# MIMXRT1064 register map
Vendor: nxp.com; File version: 1.0
CPU: CM7 r0p1, little endian, MPU, FPU, VTOR, 4 interrupt priority bits
Registers are 32-bit, read-write, reset 0x0 unless marked. A register's access mark holds for its fields unless they carry their own. Offsets are from the block's base; [hi:lo] are bit positions; {n}, {i} and the like mark numbered series; 'fields as' and 'values as' point back to an identical list.

## TMR1 — TMR
Base 0x401DC000
Same registers: TMR2 0x401E0000, TMR3 0x401E4000, TMR4 0x401E8000
0x00 COMP10 16-bit — Timer Channel Compare Register 1
  [15:0] COMPARISON_1 — Comparison Value 1
0x02 COMP20 16-bit — Timer Channel Compare Register 2
  [15:0] COMPARISON_2 — Comparison Value 2
{0x4+0x20*i} CAPT{i} 16-bit (i=0..3) — Timer Channel Capture Register
  [15:0] CAPTURE — Capture Value
{0x6+0x20*i} LOAD{i} 16-bit (i=0..3) — Timer Channel Load Register
  [15:0] LOAD — Timer Load Register
{0x8+0x20*i} HOLD{i} 16-bit (i=0..3) — Timer Channel Hold Register
  [15:0] HOLD
{0xA+0x20*i} CNTR{i} 16-bit (i=0..3) — Timer Channel Counter Register
  [15:0] COUNTER
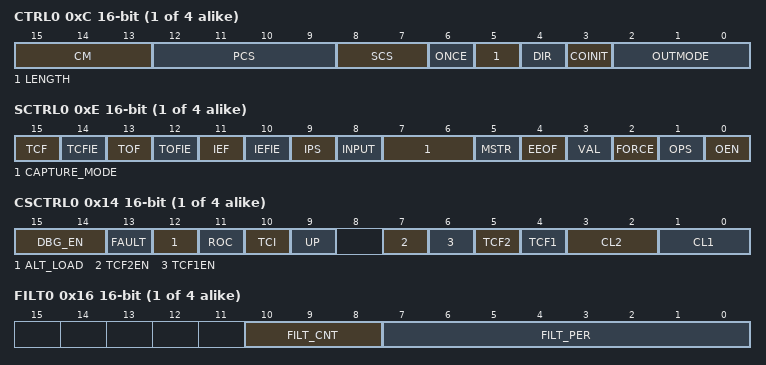
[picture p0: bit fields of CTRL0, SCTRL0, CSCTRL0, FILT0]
{0xC+0x20*i} CTRL{i} 16-bit (i=0..3) — Timer Channel Control Register
  [15:13] CM — Count Mode
    0=NOOP (No operation); 1=RISING_ONLY (Count rising edges of primary sourceRising edges are counted only when SCTRL[IPS] = 0. Falling edges are counted when SCTRL[IPS] = 1. If the primary count source is IP bus clock divide by 1, only rising edges are counted regardless of the value of SCTRL[IPS].); 2=RISING_AND_FALLING (Count rising and falling edges of primary sourceIP bus clock divide by 1 cannot be used as a primary count source in edge count mode.); 3=RISING_WHILE_SEC_HIGH (Count rising edges of primary source while secondary input high active); 4=QUADRATURE (Quadrature count mode, uses primary and secondary sources); 5=RISING_SEC_DIR (Count rising edges of primary source; secondary source specifies directionRising edges are counted only when SCTRL[IPS] = 0. Falling edges are counted when SCTRL[IPS] = 1.); 6=SECONDARY (Edge of secondary source triggers primary count until compare); 7=CASCADE (Cascaded counter mode (up/down)The primary count source must be set to one of the counter outputs.)
  [12:9] PCS — Primary Count Source
    {v}=COUNTER{v}_IN (Counter {v} input pin) (v=0..3); {v}=COUNTER{v-4}_OUT (Counter {v-4} output) (v=4..7); 8=BUS_DIVBY1 (IP bus clock divide by 1 prescaler); 9=BUS_DIVBY2 (IP bus clock divide by 2 prescaler); 10=BUS_DIVBY4 (IP bus clock divide by 4 prescaler); 11=BUS_DIVBY8 (IP bus clock divide by 8 prescaler); 12=BUS_DIVBY16 (IP bus clock divide by 16 prescaler); 13=BUS_DIVBY32 (IP bus clock divide by 32 prescaler); 14=BUS_DIVBY64 (IP bus clock divide by 64 prescaler); 15=BUS_DIVBY128 (IP bus clock divide by 128 prescaler)
  [8:7] SCS — Secondary Count Source
    {v}=COUNTER{v}_IN (Counter {v} input pin) (v=0..3)
  [6] ONCE — Count Once
    0=REPEAT (Count repeatedly.); 1=UNTIL_COMPARE (Count until compare and then stop. If counting up, a successful compare occurs when the counter reaches a COMP1 value. If counting down, a successful compare occurs when the counter reaches a COMP2 value. When output mode $4 is used, the counter re-initializes after reaching the COMP1 value, continues to count to the COMP2 value, and then stops.)
  [5] LENGTH — Count Length
    0=UNTIL_ROLLOVER (Count until roll over at $FFFF and continue from $0000.); 1=UNTIL_COMPARE (Count until compare, then re-initialize. If counting up, a successful compare occurs when the counter reaches a COMP1 value. If counting down, a successful compare occurs when the counter reaches a COMP2 value. When output mode $4 is used, alternating values of COMP1 and COMP2 are used to generate successful comparisons. For example, the counter counts until a COMP1 value is reached, re-initializes, counts until COMP2 value is reached, re-initializes, counts until COMP1 value is reached, and so on.)
  [4] DIR — Count Direction
    0=COUNTUP; 1=COUNTDOWN
  [3] COINIT — Co-Channel Initialization
    0=DISABLE (Co-channel counter/timers cannot force a re-initialization of this counter/timer); 1=ENABLE (Co-channel counter/timers may force a re-initialization of this counter/timer)
  [2:0] OUTMODE — Output Mode
    0=COUNTER_ACTIVE (Asserted while counter is active); 1=CLEAR_OFLAG (Clear OFLAG output on successful compare); 2=SET_OFLAG (Set OFLAG output on successful compare); 3=TOGGLE_OFLAG_SUCCESS (Toggle OFLAG output on successful compare); 4=TOGGLE_OFLAG_ALT (Toggle OFLAG output using alternating compare registers); 5=CLEAR_ON_SECONDARY (Set on compare, cleared on secondary source input edge); 6=CLEAR_ON_ROLLOVER (Set on compare, cleared on counter rollover); 7=ENABLE_GATED_OUT (Enable gated clock output while counter is active)
{0xE+0x20*i} SCTRL{i} 16-bit (i=0..3) — Timer Channel Status and Control Register
  [15] TCF — Timer Compare Flag
  [14] TCFIE — Timer Compare Flag Interrupt Enable
  [13] TOF — Timer Overflow Flag
  [12] TOFIE — Timer Overflow Flag Interrupt Enable
  [11] IEF — Input Edge Flag
  [10] IEFIE — Input Edge Flag Interrupt Enable
  [9] IPS — Input Polarity Select
  [8] INPUT ro — External Input Signal
  [7:6] CAPTURE_MODE — Input Capture Mode
    0=DISABLED (Capture function is disabled); 1=ENABLE_RISING (Load capture register on rising edge (when IPS=0) or falling edge (when IPS=1) of input); 2=ENABLE_FALLING (Load capture register on falling edge (when IPS=0) or rising edge (when IPS=1) of input); 3=ENABLE_BOTH (Load capture register on both edges of input)
  [5] MSTR — Master Mode
  [4] EEOF — Enable External OFLAG Force
  [3] VAL — Forced OFLAG Value
  [2] FORCE — Force OFLAG Output
  [1] OPS — Output Polarity Select
    0=TRUE (True polarity.); 1=INVERTED (Inverted polarity.)
  [0] OEN — Output Enable
    0=INPUT (The external pin is configured as an input.); 1=OFLAG_OUT (The OFLAG output signal is driven on the external pin. Other timer groups using this external pin as their input see the driven value. The polarity of the signal is determined by OPS.)
0x10 CMPLD10 16-bit — Timer Channel Comparator Load Register 1
  [15:0] COMPARATOR_LOAD_1
0x12 CMPLD20 16-bit — Timer Channel Comparator Load Register 2
  [15:0] COMPARATOR_LOAD_2
{0x14+0x20*i} CSCTRL{i} 16-bit (i=0..3) — Timer Channel Comparator Status and Control Register
  [15:14] DBG_EN — Debug Actions Enable
    0=NORMAL (Continue with normal operation during debug mode. (default)); 1=HALT_TMR (Halt TMR counter during debug mode.); 2=FORCE_0 (Force TMR output to logic 0 (prior to consideration of SCTRL[OPS]).); 3=HALT_AND_FORCE_0 (Both halt counter and force output to 0 during debug mode.)
  [13] FAULT — Fault Enable
    0=DISABLE (Fault function disabled.); 1=ENABLE (Fault function enabled.)
  [12] ALT_LOAD — Alternative Load Enable
    0=DISABLE (Counter can be re-initialized only with the LOAD register.); 1=ENABLE (Counter can be re-initialized with the LOAD or CMPLD2 registers depending on count direction.)
  [11] ROC — Reload on Capture
    0=DISABLE (Do not reload the counter on a capture event.); 1=ENABLE (Reload the counter on a capture event.)
  [10] TCI — Triggered Count Initialization Control
    0=STOP (Stop counter upon receiving a second trigger event while still counting from the first trigger event.); 1=RELOAD (Reload the counter upon receiving a second trigger event while still counting from the first trigger event.)
  [9] UP ro — Counting Direction Indicator
    0=DOWN (The last count was in the DOWN direction.); 1=UP (The last count was in the UP direction.)
  [7] TCF2EN — Timer Compare 2 Interrupt Enable
  [6] TCF1EN — Timer Compare 1 Interrupt Enable
  [5] TCF2 — Timer Compare 2 Interrupt Flag
  [4] TCF1 — Timer Compare 1 Interrupt Flag
  [3:2] CL2 — Compare Load Control 2
    0=NEVER (Never preload); 1=COMP1 (Load upon successful compare with the value in COMP1); 2=COMP2 (Load upon successful compare with the value in COMP2)
  [1:0] CL1 — Compare Load Control 1
    values as CL2
{0x16+0x20*i} FILT{i} 16-bit (i=0..3) — Timer Channel Input Filter Register
  [10:8] FILT_CNT — Input Filter Sample Count
  [7:0] FILT_PER — Input Filter Sample Period
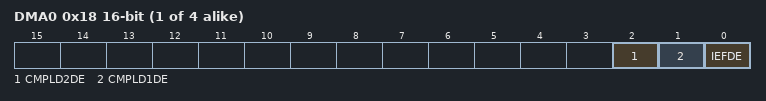
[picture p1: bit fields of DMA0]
{0x18+0x20*i} DMA{i} 16-bit (i=0..3) — Timer Channel DMA Enable Register
  [2] CMPLD2DE — Comparator Preload Register 2 DMA Enable
  [1] CMPLD1DE — Comparator Preload Register 1 DMA Enable
  [0] IEFDE — Input Edge Flag DMA Enable
0x1E ENBL 16-bit reset 0xF — Timer Channel Enable Register
  [3:0] ENBL — Timer Channel Enable
    0=DISABLE (Timer channel is disabled.); 1=ENABLE (Timer channel is enabled. (default))
0x20 COMP11 16-bit — Timer Channel Compare Register 1
  [15:0] COMPARISON_1 — Comparison Value 1
0x22 COMP21 16-bit — Timer Channel Compare Register 2
  [15:0] COMPARISON_2 — Comparison Value 2
0x30 CMPLD11 16-bit — Timer Channel Comparator Load Register 1
  [15:0] COMPARATOR_LOAD_1
0x32 CMPLD21 16-bit — Timer Channel Comparator Load Register 2
  [15:0] COMPARATOR_LOAD_2
0x40 COMP12 16-bit — Timer Channel Compare Register 1
  [15:0] COMPARISON_1 — Comparison Value 1
0x42 COMP22 16-bit — Timer Channel Compare Register 2
  [15:0] COMPARISON_2 — Comparison Value 2
0x50 CMPLD12 16-bit — Timer Channel Comparator Load Register 1
  [15:0] COMPARATOR_LOAD_1
0x52 CMPLD22 16-bit — Timer Channel Comparator Load Register 2
  [15:0] COMPARATOR_LOAD_2
0x60 COMP13 16-bit — Timer Channel Compare Register 1
  [15:0] COMPARISON_1 — Comparison Value 1
0x62 COMP23 16-bit — Timer Channel Compare Register 2
  [15:0] COMPARISON_2 — Comparison Value 2
0x70 CMPLD13 16-bit — Timer Channel Comparator Load Register 1
  [15:0] COMPARATOR_LOAD_1
0x72 CMPLD23 16-bit — Timer Channel Comparator Load Register 2
  [15:0] COMPARATOR_LOAD_2
